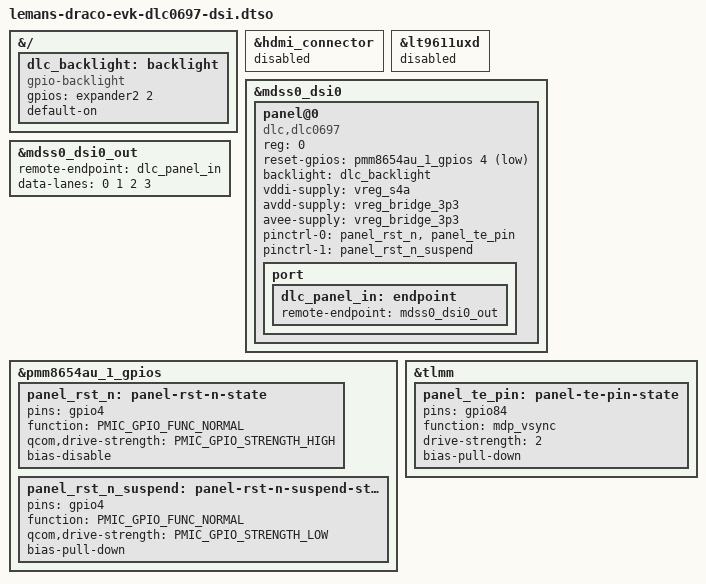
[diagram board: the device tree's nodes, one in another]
// SPDX-License-Identifier: BSD-3-Clause
/*
 * Copyright (c) Qualcomm Technologies, Inc. and/or its subsidiaries.
 */

/dts-v1/;
/plugin/;

#include <dt-bindings/gpio/gpio.h>
#include <dt-bindings/pinctrl/qcom,pmic-gpio.h>

&{/} {
	dlc_backlight: backlight {
		compatible = "gpio-backlight";
		gpios = <&expander2 2 GPIO_ACTIVE_HIGH>;
		default-on;
	};
};

&hdmi_connector {
	status = "disabled";
};

&lt9611uxd {
	status = "disabled";
};

&mdss0_dsi0 {
	status = "okay";

	#address-cells = <1>;
	#size-cells = <0>;

	panel@0 {
		compatible = "dlc,dlc0697", "ilitek,ili7807s";
		reg = <0>;
		reset-gpios = <&pmm8654au_1_gpios 4 GPIO_ACTIVE_LOW>;
		backlight = <&dlc_backlight>;
		vddi-supply = <&vreg_s4a>;
		avdd-supply = <&vreg_bridge_3p3>;
		avee-supply = <&vreg_bridge_3p3>;
		pinctrl-0 = <&panel_rst_n &panel_te_pin>;
		pinctrl-1 = <&panel_rst_n_suspend>;
		pinctrl-names = "default", "sleep";

		port {
			dlc_panel_in: endpoint {
				remote-endpoint = <&mdss0_dsi0_out>;
			};
		};
	};
};

&mdss0_dsi0_out {
	remote-endpoint = <&dlc_panel_in>;
	data-lanes = <0 1 2 3>;
};

&pmm8654au_1_gpios {
	panel_rst_n: panel-rst-n-state {
		pins = "gpio4";
		function = PMIC_GPIO_FUNC_NORMAL;
		qcom,drive-strength = <PMIC_GPIO_STRENGTH_HIGH>;
		bias-disable;
	};

	panel_rst_n_suspend: panel-rst-n-suspend-state {
		pins = "gpio4";
		function = PMIC_GPIO_FUNC_NORMAL;
		qcom,drive-strength = <PMIC_GPIO_STRENGTH_LOW>;
		bias-pull-down;
	};
};

&tlmm {
	panel_te_pin: panel-te-pin-state {
		pins = "gpio84";
		function = "mdp_vsync";
		drive-strength = <2>;
		bias-pull-down;
	};
};
